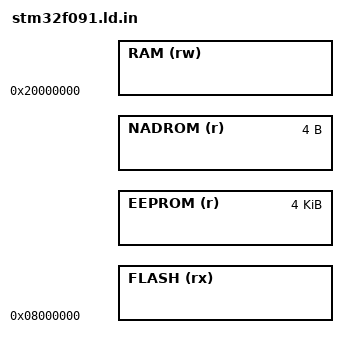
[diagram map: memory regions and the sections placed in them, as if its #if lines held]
/*****************************************************************************
* Product: Linker script for TLE9844-2Q, GNU-ARM linker
*****************************************************************************/
OUTPUT_FORMAT("elf32-littlearm", "elf32-bigarm", "elf32-littlearm")
OUTPUT_ARCH(arm)
ENTRY(Reset_Handler) /* entry Point */

// CMake configuration section
#cmakedefine NO_LIBINIT
#cmakedefine STACKSIZE @STACKSIZE@
#cmakedefine HEAPSIZE @HEAPSIZE@
#cmakedefine MCU_FLASH_SIZE @MCU_FLASH_SIZE@k
#if defined MCU_FLASH_SIZE
#   define FLASHSIZE (MCU_FLASH_SIZE)
#else
#   define FLASHSIZE (1024 * 32)
#endif


// Preprocessor definitions
FLASHSTART = 0x8000000;
RAMSIZE    = (1024 *  32); //  32kBytes of RAM
RAMSTART   = 0x20000000;

#if defined USE_EEPROM
  EEPSIZE    = 4k;
  EEPSTART = (FLASHSTART + CODESIZE);
#else
  EEPSIZE    = 0;
#endif

#if defined USE_NAD_MEMORY
  NADSIZE  = 4;
  NADSTART = (FLASHSTART + FLASHSIZE - NADSIZE);
#else
  NADSIZE  = 0;
#endif

CODESIZE = (FLASHSIZE  - EEPSIZE - NADSIZE);
RAMEND   = (RAMSTART   + RAMSIZE);
 
#if (defined(STACKSIZE) && (STACKSIZE > 0))
  PROVIDE(__stacksize = STACKSIZE);
#endif
#if (defined(HEAPSIZE) && (HEAPSIZE > 0))
  PROVIDE(__heapsize = HEAPSIZE);
#endif

MEMORY { /* memory map of Infineon TLE9844 */
    FLASH(rx) : ORIGIN = FLASHSTART, LENGTH = CODESIZE
#if defined USE_EEPROM
    EEPROM(r) : ORIGIN = EEPSTART,   LENGTH = EEPSIZE
#endif
#if defined USE_NAD_MEMORY
    NADROM(r) : ORIGIN = NADSTART,   LENGTH = NADSIZE
#endif
    RAM(rw)   : ORIGIN = RAMSTART,   LENGTH = RAMSIZE
}

REGION_ALIAS("R_VECTOR", FLASH);
REGION_ALIAS("R_TEXT",   FLASH);
REGION_ALIAS("R_RODATA", FLASH);
REGION_ALIAS("R_ARRAYS", FLASH);
#if defined USE_EEPROM
  REGION_ALIAS("R_EEPROM", EEPROM);
#endif
#if defined USE_NAD_MEMORY
  REGION_ALIAS("R_NADROM", NADROM);
#endif

REGION_ALIAS("R_DATA",   RAM);
REGION_ALIAS("R_BSS",    RAM);
REGION_ALIAS("R_NOINIT", RAM);
REGION_ALIAS("R_HEAP",   RAM);
REGION_ALIAS("R_STACK",  RAM);
REGION_ALIAS("R_EXIDX",  RAM);

#include "stm32f091_sect.ld.in"
